# MB9BF16xK register map
Vendor: Cypress; File version: 2.1
CPU: CM4 r0p1, little endian, MPU, FPU, 4 interrupt priority bits
Registers are 32-bit, read-write, reset 0x0 unless marked. A register's access mark holds for its fields unless they carry their own. Offsets are from the block's base; [hi:lo] are bit positions; {n}, {i} and the like mark numbered series.

## RTC — REAL-TIME CLOCK
Base 0x4003B100
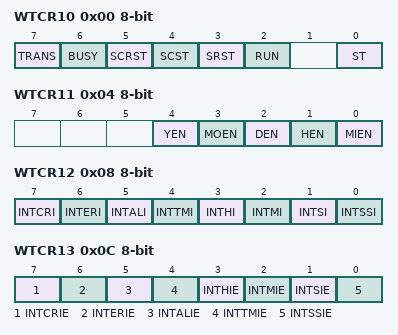
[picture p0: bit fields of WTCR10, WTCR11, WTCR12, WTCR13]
0x00 WTCR10 8-bit — Control Register 10 [BHW]
  [7] TRANS ro — Transfer flag bit
  [6] BUSY ro — Busy bit
  [5] SCRST — Sub second generation/1-second generation counter reset bit
  [4] SCST — 1-second clock output stop bit
  [3] SRST wo — RTC reset bit
  [2] RUN ro — RTC count block operation bit
  [0] ST — Start bit
0x04 WTCR11 8-bit — Control Register 11 [BHW]
  [4] YEN — Alarm year register enable bit
  [3] MOEN — Alarm month register enable bit
  [2] DEN — Alarm day register enable bit
  [1] HEN — Alarm hour register enable bit
  [0] MIEN — Alarm minute register enable bit
0x08 WTCR12 8-bit — Control Register 12 [BHW]
  [7] INTCRI — Year/month/date/hour/minute/second/day of the week counter value read completion interrupt flag bit
  [6] INTERI — Time rewrite error interrupt flag bit
  [5] INTALI — Alarm coincidence flag bit
  [4] INTTMI — Timer underflow detection flag bit
  [3] INTHI — Every hour flag bit
  [2] INTMI — Every minute flag bit
  [1] INTSI — Every second flag bit
  [0] INTSSI — Every 0.5-second flag bit
0x0C WTCR13 8-bit — Control Register 13 [BHW]
  [7] INTCRIE — Year/month/date/hour/minute/second/day of the week counter value read completion interrupt enable bit
  [6] INTERIE — Time rewrite error interrupt enable bit
  [5] INTALIE — Alarm coincidence interrupt enable bit
  [4] INTTMIE — Timer underflow interrupt enable bit
  [3] INTHIE — Every hour interrupt enable bit
  [2] INTMIE — Every minute interrupt enable bit
  [1] INTSIE — Every second interrupt enable bit
  [0] INTSSIE — Every 0.5-second interrupt enable bit
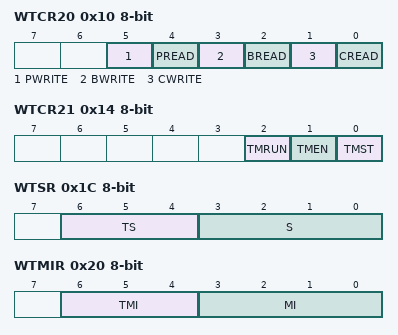
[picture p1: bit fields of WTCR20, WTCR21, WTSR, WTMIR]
0x10 WTCR20 8-bit — Control Register 20 [BHW]
  [5] PWRITE — VBAT PORT save control bit
  [4] PREAD — VBAT PORT recall control bit
  [3] BWRITE — Back up register save control bit
  [2] BREAD — Back up register recall control bit
  [1] CWRITE — RTC setting save control bit
  [0] CREAD — RTC setting recall control bit
0x14 WTCR21 8-bit — Control Register 21 [BHW]
  [2] TMRUN ro — Timer counter operation bit
  [1] TMEN — Timer counter control bit
  [0] TMST — Timer counter start bit
0x1C WTSR 8-bit — Second Register [BHW]
  [6:4] TS — 2nd digit of the second information
  [3:0] S — 1st digit of the second information
0x20 WTMIR 8-bit — Minute Register [BHW]
  [6:4] TMI — 2nd digit of the minute information
  [3:0] MI — 1st digit of the minute information
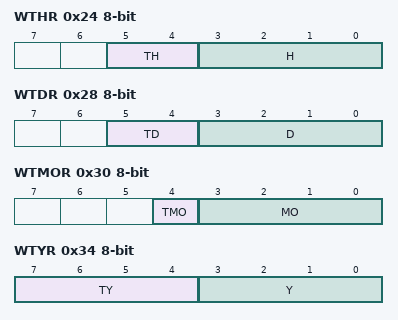
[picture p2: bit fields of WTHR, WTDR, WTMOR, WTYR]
0x24 WTHR 8-bit — Hour register [BHW]
  [5:4] TH — 2nd digit of the hour information
  [3:0] H — 1st digit of the hour information
0x28 WTDR 8-bit — Day Register [BHW]
  [5:4] TD — 2nd digit of the day information
  [3:0] D — 1st digit of the day information
0x2C WTDW 8-bit — Day of the Week Register [BHW]
  [2:0] DW — Day of the week information
0x30 WTMOR 8-bit — Month Register [BHW]
  [4] TMO — 2nd digit of the month information
  [3:0] MO — 1st digit of the month information
0x34 WTYR 8-bit — Year Register [BHW]
  [7:4] TY — 2nd digit of the year information
  [3:0] Y — 1st digit of the year information
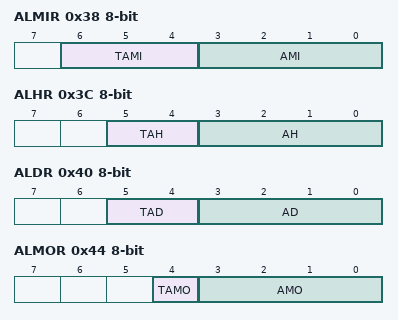
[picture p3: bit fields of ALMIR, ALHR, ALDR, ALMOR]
0x38 ALMIR 8-bit — Alarm Minute Register [BHW]
  [6:4] TAMI — 2nd digit of the alarm-set minute information
  [3:0] AMI — 1st digit of the alarm-set minute information
0x3C ALHR 8-bit — Alarm Hour Register [BHW]
  [5:4] TAH — 2nd digit of the alarm-set hour information
  [3:0] AH — 1st digit of the alarm-set hour information
0x40 ALDR 8-bit — Alarm Date Register [BHW]
  [5:4] TAD — 2nd digit of the alarm-set date information
  [3:0] AD — 1st digit of the alarm-set date information
0x44 ALMOR 8-bit — Alarm Month Register [BHW]
  [4] TAMO — 2nd digit of the alarm-set month information
  [3:0] AMO — 1st digit of the alarm-set month information
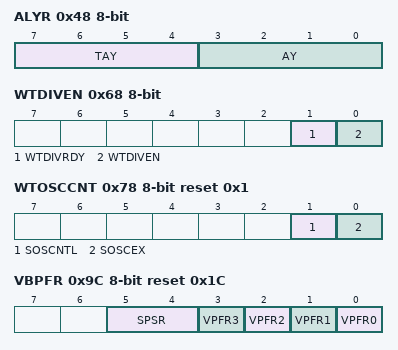
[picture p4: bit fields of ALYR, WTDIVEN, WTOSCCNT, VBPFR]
0x48 ALYR 8-bit — Alarm Years Register [BHW]
  [7:4] TAY — 2nd digit of the alarm-set year information
  [3:0] AY — 1st digit of the alarm-set year information
0x4C WTTR0 8-bit — Timer Setting Register 0 [BHW]
  [7:0] TM — Timer Setting Register
0x50 WTTR1 8-bit — Timer Setting Register 1 [BHW]
  [7:0] TM — Timer Setting Register
0x54 WTTR2 8-bit — Timer Setting Register 2 [BHW]
  [1:0] TM — Timer Setting Register
0x58 WTCAL0 8-bit — Frequency Correction Value Setting Register 0 [BHW]
  [7:0] WTCAL0 — Frequency correction value setting bits 0
0x5C WTCAL1 8-bit — Frequency Correction Value Setting Register 1 [BHW]
  [1:0] WTCAL1 — Frequency correction value setting bits 1
0x60 WTCALEN 8-bit — Frequency Correction Enable Register [BHW]
  [0] WTCALEN — Frequency correction enable bit
0x64 WTDIV 8-bit — Division Ratio Setting Register [BHW]
  [3:0] WTDIV — Division ration setting bits
0x68 WTDIVEN 8-bit — Divider Output Enable Register [BHW]
  [1] WTDIVRDY ro — Divider state bit
  [0] WTDIVEN — Divider enable bit
0x6C WTCALPRD 8-bit reset 0x13 — Frequency Correction Period Setting Register [BHW]
  [5:0] WTCALPRD — Frequency correction value setting bits
0x70 WTCOSEL 8-bit — RTCCO Output Selection Register [BHW]
  [0] WTCOSEL — RTCCO output selection bit
0x74 VB_CLKDIV 8-bit reset 0x7 — VBAT Clock Divider Register [BHW]
  [7:0] DIV — Transfer clock set bits
0x78 WTOSCCNT 8-bit reset 0x1 — WT Oscillation Circuit Control Register [BHW]
  [1] SOSCNTL — Cooperative operation control bit
  [0] SOSCEX — Oscillation enable bit
0x7C CCS 8-bit reset 0x8 — Oscillation Sustain Current Control Register [BHW]
  [7:0] CCS — Oscillation sustain current set bits
0x80 CCB 8-bit reset 0x10 — Oscillation Boost Current Control Register [BHW]
  [7:0] CCB — Oscillation boost current set bits
0x88 BOOST 8-bit reset 0x3 — Oscillation Boost Clock Setting Register [BHW]
  [1:0] BOOST — Oscillation boost time set bits
0x8C EWKUP 8-bit — Wakeup Request Register [BHW]
  [0] WUP0 — Wakeup request bit
0x90 VDET 8-bit reset 0x80 — Power-On Circuit State and Power-On Signal Register [BHW]
  [7] PON — Power-on bit
0x98 HIBRST 8-bit — Hibernation Start Register [BHW]
  [0] HIBRST — Hibernation start bit
0x9C VBPFR 8-bit reset 0x1C — Port Function Set Register [BHW]
  [5:4] SPSR — Oscillation pin function set bits
  [3] VPFR3 — Port function of P46/X0A pin set bit
  [2] VPFR2 — Port function of P47/X1A pin set bit
  [1] VPFR1 — Port function of P49/VWAKEUP pin set bit
  [0] VPFR0 — Port function of P48/VREGCTL pin set bit
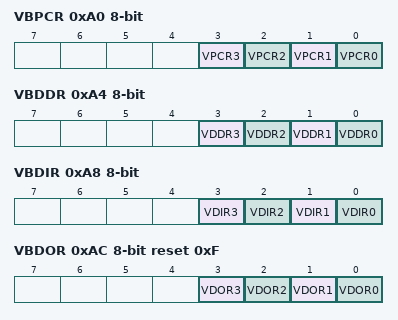
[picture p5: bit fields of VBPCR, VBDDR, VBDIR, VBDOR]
0xA0 VBPCR 8-bit — Pull-up Set Register [BHW]
  [3] VPCR3 — P46/X0A pin pull-up set bit
  [2] VPCR2 — P47/X1A pin pull-up set bit
  [1] VPCR1 — P49/VWAKEUP pin pull-up set bit
  [0] VPCR0 — P48/VREGCTL pin pull-up set bit
0xA4 VBDDR 8-bit — Port I/O Direction Set Register [BHW]
  [3] VDDR3 — Port direction of P46/X0A pin set bit
  [2] VDDR2 — Port direction of P47/X1A pin set bit
  [1] VDDR1 — Port direction of P49/VWAKEUP pin set bit
  [0] VDDR0 — Port direction of P48/VREGCTL pin set bit
0xA8 VBDIR 8-bit — Port Input Data Register [BHW]
  [3] VDIR3 — Port input data of P46/X0A pin bit
  [2] VDIR2 — Port input data of P47/X1A pin bit
  [1] VDIR1 — Port input data of P49/VWAKEUP pin bit
  [0] VDIR0 — Port input data of P48/VREGCTL pin bit
0xAC VBDOR 8-bit reset 0xF — Port Output Data Register [BHW]
  [3] VDOR3 — Port output data of P46/X0A pin bit
  [2] VDOR2 — Port output data of P47/X1A pin bit
  [1] VDOR1 — Port output data of P49/VWAKEUP pin bit
  [0] VDOR0 — Port output data of P48/VREGCTL pin bit
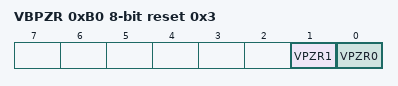
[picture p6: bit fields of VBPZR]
0xB0 VBPZR 8-bit reset 0x3 — Port Pseudo-Open Drain Set Register [BHW]
  [1] VPZR1 — P49/VWAKEUP pin pseudo-open drain set bit
  [0] VPZR0 — P48/VREGCTL pin pseudo-open drain set bit
{0x100+i} BREG{i:02} 8-bit (i=0..9) — Backup Register [BHW]
{0x10A+0x10*i} BREG{i}A 8-bit (i=0..7) — Backup Register [BHW]
{0x10B+0x10*i} BREG{i}B 8-bit (i=0..7) — Backup Register [BHW]
{0x10C+0x10*i} BREG{i}C 8-bit (i=0..7) — Backup Register [BHW]
{0x10D+0x10*i} BREG{i}D 8-bit (i=0..7) — Backup Register [BHW]
{0x10E+0x10*i} BREG{i}E 8-bit (i=0..7) — Backup Register [BHW]
{0x10F+0x10*i} BREG{i}F 8-bit (i=0..7) — Backup Register [BHW]
{0x106+i} BREG{i} 8-bit (i=10..19) — Backup Register [BHW]
{0x10C+i} BREG{i} 8-bit (i=20..29) — Backup Register [BHW]
{0x112+i} BREG{i} 8-bit (i=30..39) — Backup Register [BHW]
{0x118+i} BREG{i} 8-bit (i=40..49) — Backup Register [BHW]
{0x11E+i} BREG{i} 8-bit (i=50..59) — Backup Register [BHW]
{0x124+i} BREG{i} 8-bit (i=60..69) — Backup Register [BHW]
{0x12A+i} BREG{i} 8-bit (i=70..79) — Backup Register [BHW]

## Notices in the file
Copyright (C) 2013-2016, Cypress Semiconductor Corporation or a
subsidiary of Cypress Semiconductor Corporation.  All rights reserved.
This software, including source code, documentation and related
materials ("Software"), is owned by Cypress Semiconductor Corporation or
one of its subsidiaries ("Cypress") and is protected by and subject to
worldwide patent protection (United States and foreign), United States
copyright laws and international treaty provisions. Therefore, you may use
this Software only as provided in the license agreement accompanying the
software package from which you obtained this Software ("EULA").
If no EULA applies, Cypress hereby grants you a personal, non-exclusive,
non-transferable license to copy, modify, and compile the
Software source code solely for use in connection with Cypress's
integrated circuit products.  Any reproduction, modification, translation,
compilation, or representation of this Software except as specified
above is prohibited without the express written permission of Cypress.
Disclaimer: THIS SOFTWARE IS PROVIDED AS-IS, WITH NO
WARRANTY OF ANY KIND, EXPRESS OR IMPLIED, INCLUDING,
BUT NOT LIMITED TO, NONINFRINGEMENT, IMPLIED
WARRANTIES OF MERCHANTABILITY AND FITNESS FOR A
PARTICULAR PURPOSE. Cypress reserves the right to make
changes to the Software without notice. Cypress does not assume any
liability arising out of the application or use of the Software or any
product or circuit described in the Software. Cypress does not
authorize its products for use in any products where a malfunction or
failure of the Cypress product may reasonably be expected to result in
significant property damage, injury or death ("High Risk Product"). By
including Cypress's product in a High Risk Product, the manufacturer
of such system or application assumes all risk of such use and in doing
so agrees to indemnify Cypress against all liability.
